# IND83212 register map
Series: Verne; File version: B0
CPU: CM0 r0p1, selectable endian, no MPU, no FPU, 4 interrupt priority bits
Registers are 32-bit, read-write, no defined reset value unless marked. A register's access mark holds for its fields unless they carry their own. Offsets are from the block's base; [hi:lo] are bit positions; {n}, {i} and the like mark numbered series.

## SYSCTRLA — System configuration and retention memory
Base 0x50012000; register names take the prefix SYSCTRLA_
0x00 RETAIN0 — Retained data 0
  [7:0] RETAIN0 dual — Firmware scratch register 0. Only reset at power-on (e.g contents retained in Hibernate mode and retained despite any hard or soft resets). NOTE: The write operation of this register takes effect by PMU_SFRS->CTRL.UPDATE
0x04 RETAIN1 — Retained data 1
  [7:0] RETAIN1 — Firmware scratch register 1 (0x1). Contents retained in Hibernate mode - but lost after any hard or soft reset.
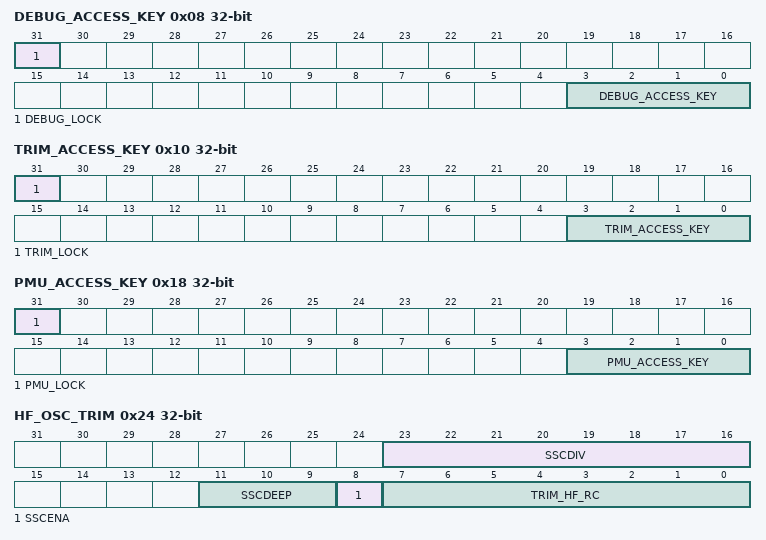
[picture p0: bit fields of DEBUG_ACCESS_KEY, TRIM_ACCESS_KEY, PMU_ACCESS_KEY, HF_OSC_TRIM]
0x08 DEBUG_ACCESS_KEY
  [31] DEBUG_LOCK — Set Only bit. Set this bit to lock DEBUG_CODE bits.
  [3:0] DEBUG_ACCESS_KEY — Write the value 0x5 to this register to enable debug options. Write any other value to disable the debug options.
0x0C DEBUG_ACCESS_ENABLED
  [0] DEBUG_ACCESS_ENABLED ro — A status flag that is set when debug access is enabled
0x10 TRIM_ACCESS_KEY
  [31] TRIM_LOCK — Set Only bit. Write 1 to this bit to lock TRIM_CODE bits.
  [3:0] TRIM_ACCESS_KEY — Write the value 0xe to this register to enable 'trim access' (which allows write access to various trim settings and production test options). Write any other value to disable trim access.
0x14 TRIM_ACCESS_ENABLED
  [0] TRIM_ACCESS_ENABLED ro — A status flag that is set when trim access is enabled
0x18 PMU_ACCESS_KEY — PMU configure access key
  [31] PMU_LOCK — Set Only bit. Set this bit to lock PMU_CODE bits.
  [3:0] PMU_ACCESS_KEY — Write the value 0xA to this register to enable 1v5 domain at hibernate. Write any other value to disable the 1v5 domain at hibernate.
0x1C PMU_ACCESS_ENABLED — PMU configure access enabled
  [0] PMU_ACCESS_ENABLED ro — A status flag that is set when pmu access is enabled
0x20 LF_OSC_TRIM — Trim controls for the low frequency (32k/250KHz) oscillators
  [7:0] TRIM_LF_RC — LF RC oscillator trim. Following value only used as a reference: NOTE: The write operation of this register takes effect by PMU_SFRS->CTRL.UPDATE and write trim key 0x0: freq=141.1KHz 0x9b: freq=250.0KHz 0xa0: freq=256.0KHz 0xff: freq=441.7KHz
0x24 HF_OSC_TRIM — Trim controls for the high frequency (16MHz) oscillator
  [23:16] SSCDIV — SSC Clock Divider. SSC Freq = SYS_FREQ/[(SSC_DIV+1)*(SSC_DEEP+1)*4].
  [11:9] SSCDEEP — SSC Depth Configuration.
  [8] SSCENA — SSC Enable.
  [7:0] TRIM_HF_RC — High Frequency RC Oscillator trim. TRIM bits will be changed if SSC is enabled. Reload the trim bits from Flash if SSC is disabled while the change has happened.write trim key. Following value only used as a reference: 0x0: freq= 9MHz 0xa7: freq=16MHz 0xff: freq=35MHz
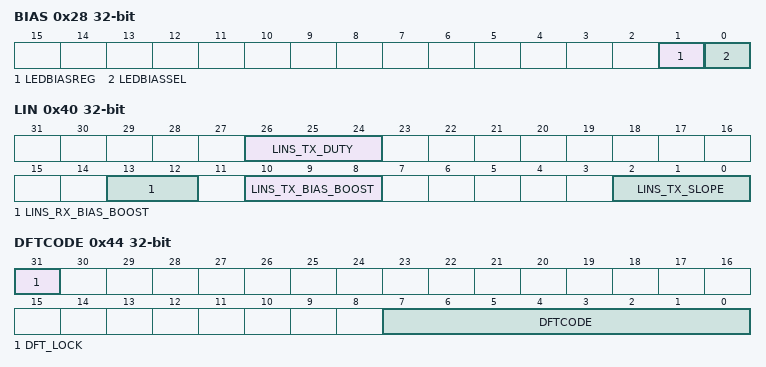
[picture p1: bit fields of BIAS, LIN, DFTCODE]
0x28 BIAS — Bias Control
  [1] LEDBIASREG — High Voltage LED bias select register. If LED_BIAS_SEL is set, then LED_BIAS_REG allows override access to the LED BIAS signal.
  [0] LEDBIASSEL — High Voltage LED bias select. 0x0: The LED Bias is enabled and disabled by the pmu hardware state machine by default. 0x1: The value of the LED_BIAS_REG field is what is used to drive the LED_BIAS signal. (override mode)
0x2C TRIMLEDBIAS — LED bias current Trim
  [7:0] LEDBIASTRIM — LED bias current trim. each code is about 50nA step.wirte trim key
{0x30+4i} TRIMLED{i} (i=0..2) — High Voltage LED trim
  [24:16] TRIM{i} — LED trim (120uA step; max about 60mA).
0x3C TRIMVFW — VFW Current Trim
  [7:0] TRIMVFW — PN Forward Voltage Current trim (10uA step max about 2.56mA).
0x40 LIN — LIN IO Control (Trim access need to be enabled before Written)
  [26:24] LINS_TX_DUTY — LIN Slave IO Duty cycle adjust.The write operation of this register takes effect by PMU_SFRS->CTRL.UPDATE and wirte trim key 0x0: duty cycle = 0.488 0x1: duty cycle = 0.492 0x2: duty cycle = 0.494 0x3: duty cycle = 0.495 0x0: duty cycle = 0.497 0x1: duty cycle = 0.500 0x2: duty cycle = 0.507 0x3: duty cycle = 0.529
  [13:12] LINS_RX_BIAS_BOOST — adjust rise delay from LIN_IN to Input of LINS Controller.The write operation of this register takes effect by PMU_SFRS->CTRL.UPDATE and wirte trim key 0x0: 2.323 us 0x1: 1.344 us 0x2: 0.968 us 0x3: 0.767 us
  [10:8] LINS_TX_BIAS_BOOST — Select boost of LIN Slave TX IO Current, it should be within 40mA ~ 200mA.The write operation of this register takes effect by PMU_SFRS->CTRL.UPDATE and wirte trim key 0x0: 31.4 mA 0x1: 48.6 mA 0x2: 66.2 mA 0x3: 88.2 mA 0x4: 101.2 mA 0x5: 117.9 mA 0x6: 135.2 mA 0x7: 151.5 mA
  [2:0] LINS_TX_SLOPE — boost TX driver slew rate of LIN_IN,Slew from 40%*Vbat to 60%*Vbat @Vbat=13V,Cbus=1nF.The write operation of this register takes effect by PMU_SFRS->CTRL.UPDATE and wirte trim key 0x0: slewRate_pos = 0.62V/us, slewRate_neg = 0.63V/us 0x1: slewRate_pos = 0.62V/us, slewRate_neg = 0.63V/us 0x2: slewRate_pos = 1.19V/us, slewRate_neg = 1.27V/us 0x3: slewRate_pos = 1.74V/us, slewRate_neg = 1.88V/us 0x4: slewRate_pos = 2.31V/us, slewRate_neg = 2.42V/us 0x5: slewRate_pos = 2.79V/us, slewRate_neg = 2.99V/us 0x6: slewRate_pos = 3.37V/us, slewRate_neg = 3.51V/us 0x7: slewRate_pos = 5.14V/us, slewRate_neg = 16.69V/us
0x44 DFTCODE — DFT Unlock Code
  [31] DFT_LOCK — Set Only bit. Write 1 to this bit to lock DFT related config bits.
  [7:0] DFTCODE wo — Test Mode Unlock Enable Code. 0x1C needs to be written to this register to unlock the DFT_TESTMODE_SEL and DFT_TESTMODE_START registers.
0x48 DFT_ACCESS_ENABLED
  [0] DFT_ACCESS_ENABLED ro — A status flag that is set when DFT access is enabled.
0x4C DFTTESTMODESTART — DFT Mode Start
  [0] DFTTESTMODESTART wo — Puts the ASIC into DFT testmode. Once the start bit is set, the I/O configuration will switch from Application mode to DFT Test Mode. The General Purpose I/Os will be configured as a JTAG interface. Once Test Mode is enabled, the ASIC will be boundary terminated and the processor will lose the ability to communicate with any ASIC peripherals. A chip power cycle is required to get out of the DFT test mode. Test Mode Enable state.
0x50 NAME — ASIC name
  [31:0] NAME ro — ASIC name. A read from this register will return the ASIC name
0x54 REV — Silicon Revision
  [15:0] REV ro — Silicon Revision. A read from this register will return the ASCII silicon revision (e.g. ASCII C0 is 0x4331)
0x58 BORTESTMODE — BOR Testmode Enable
  [0] ENABORTESTMODE — BOR Testmode Enable. 0x0: BOR Testmode Disabled: Reference Voltage for BOR is from Band Gap (Functional Mode) 0x1: BOR Testmode Enabled: Reference Voltage for BOR is from gpio1_anaOut (Test Mode
